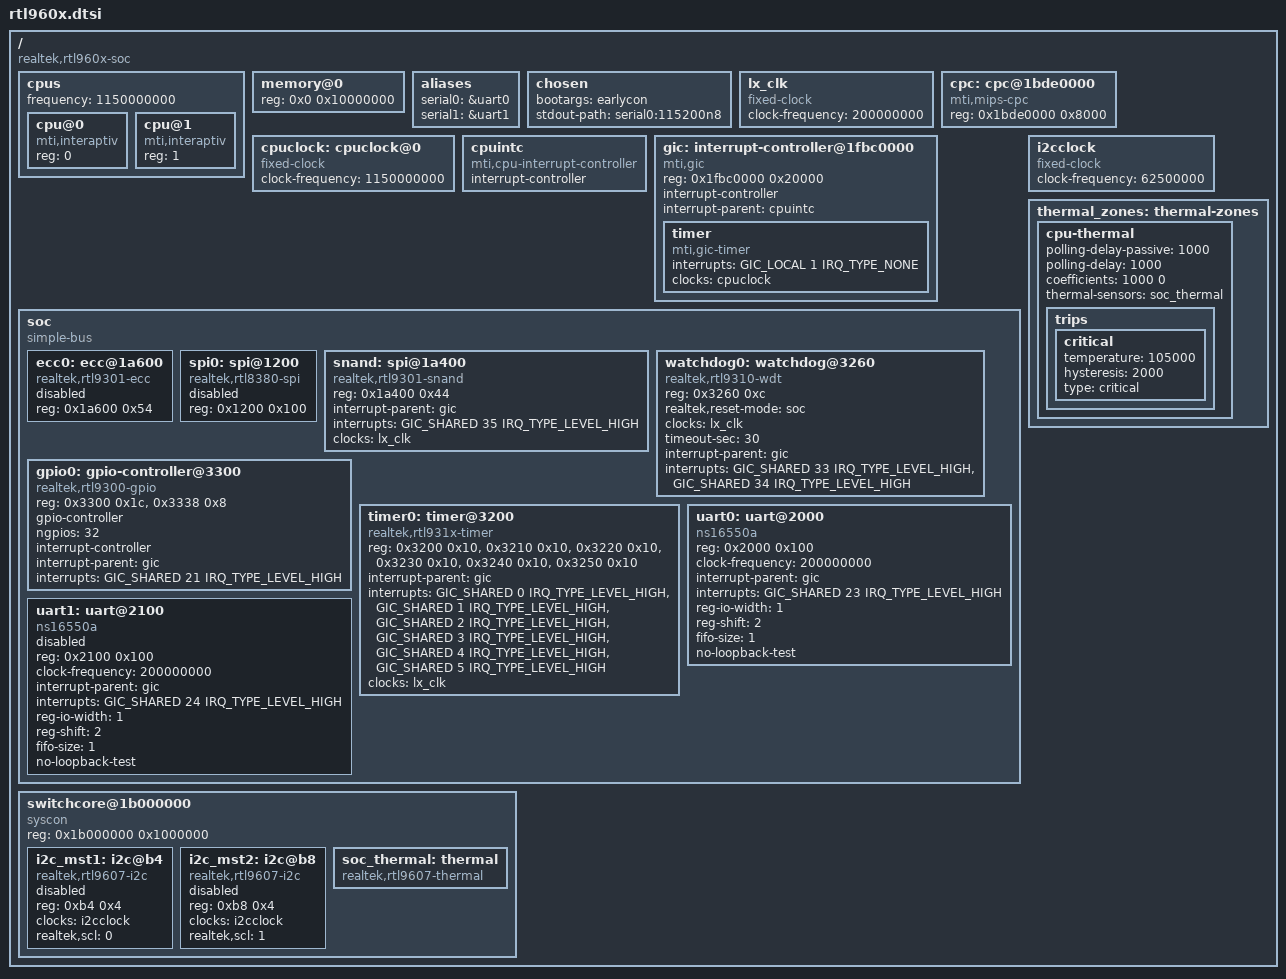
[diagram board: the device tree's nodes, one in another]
// SPDX-License-Identifier: GPL-2.0-or-later OR MIT

#include <dt-bindings/interrupt-controller/mips-gic.h>
#include <dt-bindings/interrupt-controller/irq.h>

/ {
	#address-cells = <1>;
	#size-cells = <1>;

	compatible = "realtek,rtl960x-soc";

	cpus {
		#address-cells = <1>;
		#size-cells = <0>;
		frequency = <1150000000>;

		cpu@0 {
			compatible = "mti,interaptiv";
			device_type = "cpu";
			reg = <0>;
		};
		cpu@1 {
			compatible = "mti,interaptiv";
			device_type = "cpu";
			reg = <1>;
		};
	};

	memory@0 {
		device_type = "memory";
		reg = <0x0 0x10000000>;
	};

	aliases {
		serial0 = &uart0;
		serial1 = &uart1;
	};

	chosen {
		bootargs = "earlycon";
		stdout-path = "serial0:115200n8";
	};

	lx_clk: lx_clk {
		compatible = "fixed-clock";
		#clock-cells = <0>;
		clock-frequency = <200000000>;
	};

	cpc: cpc@1bde0000 {
		compatible = "mti,mips-cpc";
		reg = <0x1bde0000 0x8000>;
	};

	cpuclock: cpuclock@0 {
		#clock-cells = <0>;
		compatible = "fixed-clock";

		/* FIXME: there should be way to detect this */
		clock-frequency = <1150000000>;
	};

	cpuintc: cpuintc {
		compatible = "mti,cpu-interrupt-controller";
		#address-cells = <0>;
		#interrupt-cells = <1>;
		interrupt-controller;
	};

	gic: interrupt-controller@1fbc0000 {
		compatible = "mti,gic";
		reg = <0x1fbc0000 0x20000>;

		interrupt-controller;
		#interrupt-cells = <3>;

		interrupt-parent = <&cpuintc>;

		timer {
			compatible = "mti,gic-timer";
			interrupts = <GIC_LOCAL 1 IRQ_TYPE_NONE>;
			clocks = <&cpuclock>;
		};
	};

	soc: soc {
		compatible = "simple-bus";
		#address-cells = <1>;
		#size-cells = <1>;
		ranges = <0x0 0x18000000 0x20000>;

		ecc0: ecc@1a600 {
			compatible = "realtek,rtl9301-ecc";
			reg = <0x1a600 0x54>;

			status = "disabled";
		};

		spi0: spi@1200 {
			status = "disabled";

			compatible = "realtek,rtl8380-spi";
			reg = <0x1200 0x100>;

			#address-cells = <1>;
			#size-cells = <0>;
		};

		snand: spi@1a400 {
			compatible = "realtek,rtl9301-snand";
			reg = <0x1a400 0x44>;
			interrupt-parent = <&gic>;
			interrupts = <GIC_SHARED 35 IRQ_TYPE_LEVEL_HIGH>;
			clocks = <&lx_clk>;
			#address-cells = <1>;
			#size-cells = <0>;
		};

		watchdog0: watchdog@3260 {
			compatible = "realtek,rtl9310-wdt";
			reg = <0x3260 0xc>;

			realtek,reset-mode = "soc";

			clocks = <&lx_clk>;
			timeout-sec = <30>;

			interrupt-parent = <&gic>;
			interrupt-names = "phase1", "phase2";
			interrupts = <GIC_SHARED 33 IRQ_TYPE_LEVEL_HIGH>, <GIC_SHARED 34 IRQ_TYPE_LEVEL_HIGH>;
		};

		gpio0: gpio-controller@3300 {
			compatible = "realtek,rtl9300-gpio", "realtek,otto-gpio";
			reg = <0x3300 0x1c>, <0x3338 0x8>;

			gpio-controller;
			#gpio-cells = <2>;
			ngpios = <32>;

			interrupt-controller;
			#interrupt-cells = <2>;
			interrupt-parent = <&gic>;
			interrupts = <GIC_SHARED 21 IRQ_TYPE_LEVEL_HIGH>;
		};

		timer0: timer@3200 {
			compatible = "realtek,rtl931x-timer", "realtek,otto-timer";
			reg = <0x3200 0x10>, <0x3210 0x10>, <0x3220 0x10>,
			      <0x3230 0x10>, <0x3240 0x10>, <0x3250 0x10>;

			interrupt-parent = <&gic>;
			interrupts = <GIC_SHARED 0 IRQ_TYPE_LEVEL_HIGH>, <GIC_SHARED 1 IRQ_TYPE_LEVEL_HIGH>,
				     <GIC_SHARED 2 IRQ_TYPE_LEVEL_HIGH>, <GIC_SHARED 3 IRQ_TYPE_LEVEL_HIGH>,
				     <GIC_SHARED 4 IRQ_TYPE_LEVEL_HIGH>, <GIC_SHARED 5 IRQ_TYPE_LEVEL_HIGH>;
			clocks = <&lx_clk>;
		};

		uart0: uart@2000 {
			compatible = "ns16550a";
			reg = <0x2000 0x100>;

			clock-frequency = <200000000>;

			interrupt-parent = <&gic>;
			#interrupt-cells = <3>;
			interrupts = <GIC_SHARED 23 IRQ_TYPE_LEVEL_HIGH>;

			reg-io-width = <1>;
			reg-shift = <2>;
			fifo-size = <1>;
			no-loopback-test;
		};

		uart1: uart@2100 {
			compatible = "ns16550a";
			reg = <0x2100 0x100>;

			clock-frequency = <200000000>;

			interrupt-parent = <&gic>;
			#interrupt-cells = <3>;
			interrupts = <GIC_SHARED 24 IRQ_TYPE_LEVEL_HIGH>;

			reg-io-width = <1>;
			reg-shift = <2>;
			fifo-size = <1>;
			no-loopback-test;

			status = "disabled";
		};
	};

	i2cclock: i2cclock {
		#clock-cells = <0>;
		compatible = "fixed-clock";

		/* 62.5 MHz */
		clock-frequency = <62500000>;
	};

	switchcore@1b000000 {
		compatible = "syscon", "simple-mfd";
		reg = <0x1b000000 0x1000000>;
		#address-cells = <1>;
		#size-cells = <1>;

		i2c_mst1: i2c@b4 {
			compatible = "realtek,rtl9607-i2c";
			reg = <0xb4 0x4>;
			#address-cells = <1>;
			#size-cells = <0>;
			clocks = <&i2cclock>;
			realtek,scl = <0>;

			status = "disabled";
		};

		i2c_mst2: i2c@b8 {
			compatible = "realtek,rtl9607-i2c";
			reg = <0xb8 0x4>;
			#address-cells = <1>;
			#size-cells = <0>;
			clocks = <&i2cclock>;
			realtek,scl = <1>;

			status = "disabled";
		};

		soc_thermal: thermal {
			compatible = "realtek,rtl9607-thermal";
			#thermal-sensor-cells = <0>;
		};
	};

	thermal_zones: thermal-zones {
		cpu-thermal {
			polling-delay-passive = <1000>;
			polling-delay = <1000>;
			coefficients = <1000 0>;
			thermal-sensors = <&soc_thermal>;
			trips {
				critical {
					temperature = <105000>;
					hysteresis = <2000>;
					type = "critical";
				};
			};
		};
	};
};
